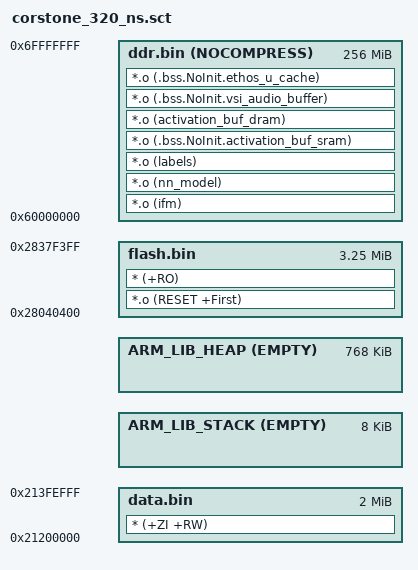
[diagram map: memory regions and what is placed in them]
#! armclang --target=arm-arm-none-eabi -march=armv8.1-m.main+mve.fp+fp.dp -E -x c
/*
 * Copyright (c) 2021-2024, Arm Limited. All rights reserved.
 *
 * Licensed under the Apache License, Version 2.0 (the "License");
 * you may not use this file except in compliance with the License.
 * You may obtain a copy of the License at
 *
 *     http://www.apache.org/licenses/LICENSE-2.0
 *
 * Unless required by applicable law or agreed to in writing, software
 * distributed under the License is distributed on an "AS IS" BASIS,
 * WITHOUT WARRANTIES OR CONDITIONS OF ANY KIND, either express or implied.
 * See the License for the specific language governing permissions and
 * limitations under the License.
 */

#define FLASH_NS_PARTITION_SIZE 0x340000
#define FLASH_S_PARTITION_SIZE  0x40000
#define ROM_START               0x28000000
#define BL2_HEADER_SIZE         0x400
#define BL2_TRAILER_SIZE        0xC00
#define ISRAM0_BASE_ADDRESS     0x21000000
#define ISRAM1_OFFSET           0x00200000
#define ISRAM1_SIZE             0x00200000
#define PROVISIONING_SIZE       0x1000
#define STACK_SIZE              0x00002000
#define HEAP_SIZE               0x000C0000

LOAD_REGION_0 (ROM_START + ((((0) + (FLASH_S_PARTITION_SIZE)) + BL2_HEADER_SIZE)))
{
    flash.bin (ROM_START + ((((0) + (FLASH_S_PARTITION_SIZE)) + BL2_HEADER_SIZE))) (((FLASH_NS_PARTITION_SIZE) - BL2_HEADER_SIZE - BL2_TRAILER_SIZE)) {
        *.o (RESET +First)
        * (+RO)
    }

    ; The last 0x1000 bytes are reserved for the provisioning bundle
    data.bin (ISRAM0_BASE_ADDRESS + ((ISRAM1_OFFSET))) (ISRAM1_SIZE - PROVISIONING_SIZE) {
        * (+ZI +RW)
    }


    ARM_LIB_STACK +0 ALIGN 32 EMPTY (STACK_SIZE) {
    }

    ARM_LIB_HEAP +0 ALIGN 8 EMPTY (HEAP_SIZE) {
    }
}

;---------------------------------------------------------
; Second load region (DDR)
;---------------------------------------------------------
LOAD_REGION_1       0x60000000                   0x10000000
{
    ;-----------------------------------------------------
    ; 32 MiB of DDR space for neural network model,
    ; input vectors and labels. If the activation buffer
    ; size required by the network is bigger than the
    ; SRAM size available, it is accommodated here.
    ;-----------------------------------------------------
    ddr.bin         0x60000000 NOCOMPRESS ALIGN 16 0x10000000
    {
        ; nn model's baked in input matrices
        *.o (ifm)

        ; nn model
        *.o (nn_model)

        ; labels
        *.o (labels)

        ; activation buffers a.k.a tensor arena when
        ; memory mode sram only or shared sram
        *.o (.bss.NoInit.activation_buf_sram)

        ; activation buffers a.k.a tensor arena when memory mode dedicated sram
        *.o (activation_buf_dram)

        ; Buffer for transferring VSI audio data from S to NS
        *.o (.bss.NoInit.vsi_audio_buffer)

        ; Cache area (if used)
        *.o (.bss.NoInit.ethos_u_cache)
    }
}
